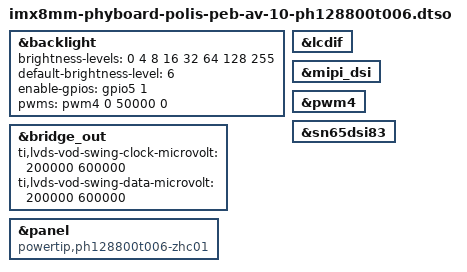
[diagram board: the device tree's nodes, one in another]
// SPDX-License-Identifier: (GPL-2.0-or-later OR MIT)
/*
 * Copyright (C) 2025 PHYTEC Messtechnik GmbH
 */

/dts-v1/;
/plugin/;

#include <dt-bindings/gpio/gpio.h>
#include "imx8mm-phyboard-polis-peb-av-10.dtsi"

&backlight {
	brightness-levels = <0 4 8 16 32 64 128 255>;
	default-brightness-level = <6>;
	enable-gpios = <&gpio5 1 GPIO_ACTIVE_HIGH>;
	pwms = <&pwm4 0 50000 0>;
	status = "okay";
};

&bridge_out {
	ti,lvds-vod-swing-clock-microvolt = <200000 600000>;
	ti,lvds-vod-swing-data-microvolt = <200000 600000>;
};

&lcdif {
	status = "okay";
};

&mipi_dsi {
	status = "okay";
};

&panel {
	compatible = "powertip,ph128800t006-zhc01";
	status = "okay";
};

&pwm4 {
	status = "okay";
};

&sn65dsi83 {
	status = "okay";
};
